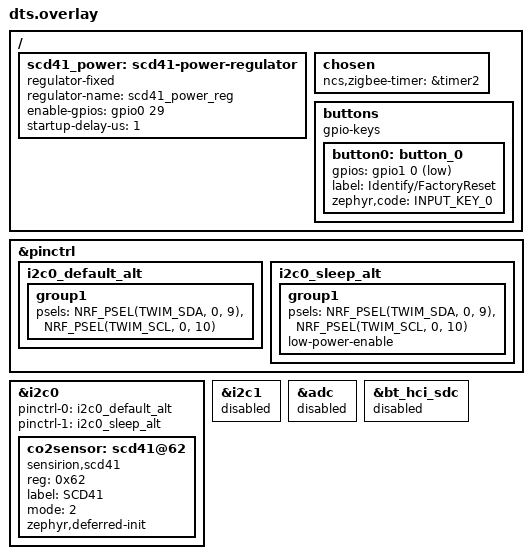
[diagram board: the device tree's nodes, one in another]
/ {
    /* Define the GPIO-controlled regulator */
    scd41_power: scd41-power-regulator {
        compatible = "regulator-fixed"; // Standard binding for fixed regulators
        regulator-name = "scd41_power_reg";
        status = "okay";

        /* GPIO controlling the MOSFET gate */
        /* GPIO_ACTIVE_HIGH means the sensor is ON when GPIO is high */
        /* Use GPIO_ACTIVE_LOW if your MOSFET logic is inverted */
        enable-gpios = <&gpio0 29 GPIO_ACTIVE_HIGH>;

        /* Optional: Define the voltage being regulated */
        // regulator-min-microvolt = ; // e.g., 3.3V
        // regulator-max-microvolt = ; // e.g., 3.3V

        /* Optional: Delay after enabling GPIO before regulator is considered stable */
        startup-delay-us = <1>; // 1us, adjust based on MOSFET and sensor VCC rise time

        /* Optional: Specify that this regulator should be off initially */
        // regulator-boot-on; // Remove or comment out if you want it initially OFF
    };

	chosen {
		ncs,zigbee-timer = &timer2;
	};

	buttons {
		compatible = "gpio-keys";
		button0: button_0 {
			gpios = <&gpio1 0 (GPIO_PULL_UP | GPIO_ACTIVE_LOW)>;
			label = "Identify/FactoryReset";
			zephyr,code = <INPUT_KEY_0>;
		};
	};
};
&pinctrl {
   i2c0_default_alt: i2c0_default_alt {
      group1 {
         psels = <NRF_PSEL(TWIM_SDA, 0, 9)>,
                 <NRF_PSEL(TWIM_SCL, 0, 10)>;
      };
   };
   i2c0_sleep_alt: i2c0_sleep_alt {
      group1 {
         psels = <NRF_PSEL(TWIM_SDA, 0, 9)>,
                 <NRF_PSEL(TWIM_SCL, 0, 10)>;
         low-power-enable;
      };
   };
};
&i2c0 {
    status = "okay";
    pinctrl-0 = <&i2c0_default_alt>;
    pinctrl-1 = <&i2c0_sleep_alt>;
    pinctrl-names = "default", "sleep";

    co2sensor: scd41@62{
        compatible="sensirion,scd41";
        reg = <0x62>;
        label = "SCD41";
        /* mode 2 = single shot */
        /* mode 1 = low power */
        /* mode 0 = normal */
        mode = < 2 >;
        status = "okay";
		zephyr,deferred-init;
    };
};
&i2c1 {
    status = "disabled";
};
&adc {
    status = "disabled";
};
&bt_hci_sdc {
    status = "disabled";
};
